# R7FA0E107 register map
Vendor: Renesas Electronics Corporation; Series: RA0; File version: 1.10.00
CPU: CM23 r1p0, little endian, no MPU, no FPU, VTOR, 2 interrupt priority bits, 64 interrupts
Registers are 16-bit, read-write, reset 0x0 unless marked. A register's access mark holds for its fields unless they carry their own. Offsets are from the block's base; [hi:lo] are bit positions; {n}, {i} and the like mark numbered series.

## SAU1 — Serial Array Unit 1
Base 0x400A2200
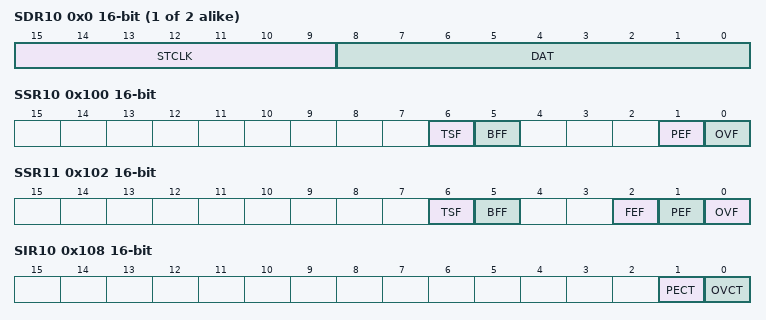
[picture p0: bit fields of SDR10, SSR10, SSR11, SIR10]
{0x0+2i} SDR1{i} (i=0..1) — Serial Data Register 1{i}
  [15:9] STCLK — Transfer Clock Setting by Dividing the Operation Clock
  [8:0] DAT — Data Buffer for Transmit and Receive
0x100 SSR10 ro — Serial Status Register 10
  [6] TSF — Flag Indicating the State of Communications for Channel n
  [5] BFF — Flag Indicating the State of the Buffer Register for Channel n
  [1] PEF — Parity or ACK Error Detection Flag of Channel n
  [0] OVF — Overrun Error Detection Flag of Channel n
0x102 SSR11 ro — Serial Status Register 11
  [6] TSF — Flag Indicating the State of Communications for Channel n
  [5] BFF — Flag Indicating the State of the Buffer Register for Channel n
  [2] FEF — Framing Error Detection Flag of Channel n
  [1] PEF — Parity or ACK Error Detection Flag of Channel n
  [0] OVF — Overrun Error Detection Flag of Channel n
0x108 SIR10 — Serial Flag Clear Trigger Register 10
  [1] PECT — Clear Trigger of Parity Error Flag of Channel n
  [0] OVCT — Clear Trigger of Overrun Error Flag of Channel n
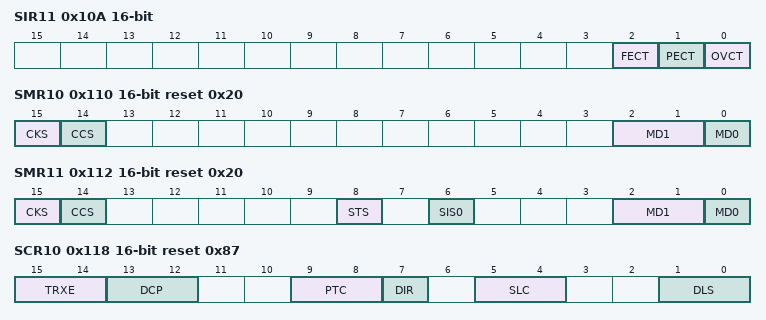
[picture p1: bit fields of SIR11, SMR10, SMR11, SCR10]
0x10A SIR11 — Serial Flag Clear Trigger Register 11
  [2] FECT — Clear Trigger of Framing Error Flag of Channel n
  [1] PECT — Clear Trigger of Parity Error Flag of Channel n
  [0] OVCT — Clear Trigger of Overrun Error Flag of Channel n
0x110 SMR10 reset 0x20 — Serial Mode Register 10
  [15] CKS — Selection of Operation Clock (fMCK) of Channel n
  [14] CCS — Selection of Transfer Clock (fTCLK) of Channel n
  [2:1] MD1 — Setting of Channel n Operation Mode
  [0] MD0 — Selection of Channel n Interrupt Source
0x112 SMR11 reset 0x20 — Serial Mode Register 11
  [15] CKS — Selection of Operation Clock (fMCK) of Channel n
  [14] CCS — Selection of Transfer Clock (fTCLK) of Channel n
  [8] STS — Selection of Start Trigger Source
  [6] SIS0 — Controls Inversion of Level of Channel n Receive Data in UART Mode
  [2:1] MD1 — Setting of Channel n Operation Mode
  [0] MD0 — Selection of Channel n Interrupt Source
0x118 SCR10 reset 0x87 — Serial Communication Operation Setting Register 10
  [15:14] TRXE — Setting of Channel 0 Operation Mode
  [13:12] DCP — Selection of Data and Clock Phase in Simplified SPI Mode
  [9:8] PTC — Setting of Parity Bit in UART Mode
  [7] DIR — Selection of Data Transfer Sequence in Simplified SPI and UART Modes
  [5:4] SLC — Setting of Stop Bit in UART Mode
  [1:0] DLS — Setting of Data Length in Simplified SPI and UART Modes
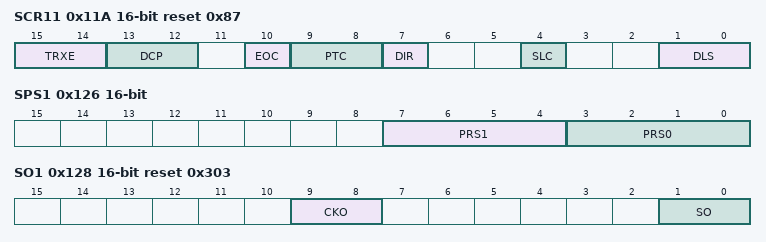
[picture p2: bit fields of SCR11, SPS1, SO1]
0x11A SCR11 reset 0x87 — Serial Communication Operation Setting Register 11
  [15:14] TRXE — Setting of Channel 1 Operation Mode
  [13:12] DCP — Selection of Data and Clock Phase in Simplified SPI Mode
  [10] EOC — Mask Control of Error Interrupt Signal SAU0_UART_ERRI0 (m = 0), SAU1_UART_ERRI2 (m = 1)
  [9:8] PTC — Setting of Parity Bit in UART Mode
  [7] DIR — Selection of Data Transfer Sequence in Simplified SPI and UART Modes
  [4] SLC — Setting of Stop Bit in UART Mode
  [1:0] DLS — Setting of Data Length in Simplified SPI and UART Modes
0x120 SE1 ro — Serial Channel Enable Status Register 1
  [1:0] SE — Indication of whether Operation of Channel n is Enabled or Stopped.
0x122 SS1 — Serial Channel Start Register 1
  [1:0] SS — Operation Start Trigger of Channel n
0x124 ST1 — Serial Channel Stop Register 1
  [1:0] ST — Operation Stop Trigger of Channel n
0x126 SPS1 — Serial Clock Select Register 1
  [7:4] PRS1 — Selection of Operation Clock (CKm1)
  [3:0] PRS0 — Selection of Operation Clock (CKm0)
0x128 SO1 reset 0x303 — Serial Output Register 1
  [9:8] CKO — Serial Clock Output of Channel n
  [1:0] SO — Serial Data Output of Channel n
0x12A SOE1 — Serial Output Enable Register 1
  [1:0] SOE — Serial Output Enable or Stop of Channel n
0x134 SOL1 — Serial Output Level Register 1
  [0] SOL0 — Selects Inversion of the Level of the Transmit Data of Channel 0 in UART Mode
